VERSION ""

NS_ :

BS_:

BU_: ADAS Master
VAL_TABLE_ TestECUState 1 "ON" 0 "OFF" ;
VAL_TABLE_ vtbSensorReqCause 15 "SNA" 2 "by Request 2" 1 "by Request 1" 0 "normal cycle" ;
VAL_TABLE_ vtbErrorDescription 255 "ERROR" ;

BO_ 3221225472 VECTOR__INDEPENDENT_SIG_MSG: 0 Vector__XXX
 SG_ sig_neg_respond : 0|8@1- (1,0) [0|0] "" Vector__XXX

BO_ 130 AEB_Info_ECU: 1 Vector__XXX
 SG_ sig_aeb_active : 0|1@1+ (1,0) [0|1] "flag"  ADAS

BO_ 515 OBD_Neg_Respond_OBD: 2 Master
 SG_ sig_sid : 8|8@1- (1,0) [0|0] ""  ADAS
 SG_ sig_neg_respond : 0|8@1- (1,0) [0|0] ""  ADAS

BO_ 514 OBD_Pos_Respond_OBD: 1 Master
 SG_ sig_sid : 0|8@1- (1,0) [0|0] ""  ADAS

BO_ 1672 VUM_File_ADAS: 8 Master
 SG_ sig_payload : 0|64@1- (1,0) [0|0] ""  ADAS

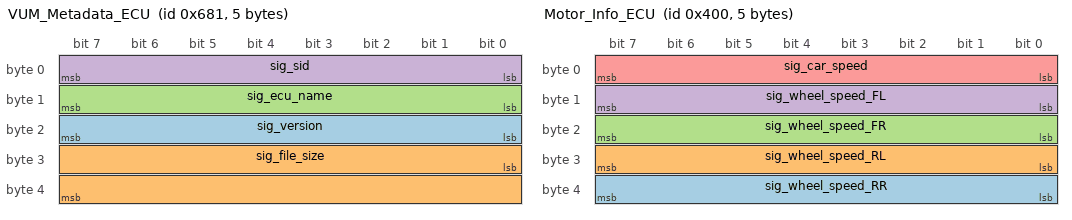
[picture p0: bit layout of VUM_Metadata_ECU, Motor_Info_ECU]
BO_ 1665 VUM_Metadata_ECU: 5 Master
 SG_ sig_version : 16|8@1+ (1,0) [0|255] ""  ADAS
 SG_ sig_file_size : 24|16@1+ (1,0) [0|65535] ""  ADAS
 SG_ sig_ecu_name : 8|8@1+ (1,0) [0|255] ""  ADAS
 SG_ sig_sid : 0|8@1+ (1,0) [0|255] ""  ADAS

BO_ 1664 VUM_Request_ECU: 1 Master
 SG_ sig_sid : 0|8@1- (1,0) [0|0] ""  ADAS

BO_ 1219 Steering_Angle_Info_ECU: 1 Master
 SG_ sig_steering_angle : 0|8@1- (1,0) [0|0] ""  ADAS

BO_ 1057 Transmission_Info_ECU: 1 Master
 SG_ sig_gear_mode : 0|2@1- (1,0) [0|0] ""  ADAS

BO_ 1024 Motor_Info_ECU: 5 Master
 SG_ sig_wheel_speed_RR : 32|8@1- (1,0) [0|0] ""  ADAS
 SG_ sig_wheel_speed_RL : 24|8@1- (1,0) [0|0] ""  ADAS
 SG_ sig_wheel_speed_FR : 16|8@1- (1,0) [0|0] ""  ADAS
 SG_ sig_wheel_speed_FL : 8|8@1- (1,0) [0|0] ""  ADAS
 SG_ sig_car_speed : 0|8@1- (1,0) [0|0] ""  ADAS

BO_ 1286 ADAS_Neg_Respond_OTA: 2 ADAS
 SG_ sig_sid : 8|8@1- (1,0) [0|0] ""  Master
 SG_ sig_neg_respond : 0|8@1- (1,0) [0|0] ""  Master

BO_ 1285 ADAS_Pos_Respond_OTA: 8 ADAS
 SG_ sig_data : 16|56@1- (1,0) [0|0] ""  Master
 SG_ sig_sid : 0|8@1- (1,0) [0|0] ""  Master

BO_ 260 ADAS_Request_OBD: 1 ADAS
 SG_ sig_sid : 0|8@1- (1,0) [0|0] ""  Master

BO_ 259 ADAS_Control_Brake: 1 ADAS
 SG_ sig_control_aeb : 0|1@1- (1,0) [0|0] ""  Master

BO_ 1282 ADAS_Control_Steering: 2 ADAS
 SG_ sig_control_steering : 0|10@1- (1,0) [0|0] ""  Master

BO_ 1281 ADAS_Control_Motor: 2 ADAS
 SG_ sig_control_accerleration : 0|10@1- (1,0) [0|0] ""  Master

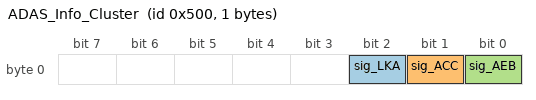
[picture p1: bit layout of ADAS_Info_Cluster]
BO_ 1280 ADAS_Info_Cluster: 1 ADAS
 SG_ sig_LKA : 2|1@1- (1,0) [0|0] ""  Master
 SG_ sig_ACC : 1|1@1- (1,0) [0|0] ""  Master
 SG_ sig_AEB : 0|1@1- (1,0) [0|0] ""  Master

CM_ BO_ 3221225472 "This is a message for not used signals, created by Vector CANdb++ DBC OLE DB Provider.";
BA_DEF_  "DatabaseVersion" STRING ;
BA_DEF_ BO_  "DiagResponse" ENUM  "No","Yes","vector_leerstring";
BA_DEF_ BO_  "DiagRequest" ENUM  "No","Yes","vector_leerstring";
BA_DEF_  "Manufacturer" STRING ;
BA_DEF_ BU_  "NodeLayerModules" STRING ;
BA_DEF_  "BusType" STRING ;
BA_DEF_ SG_  "GenSigSendType" ENUM  "Cyclic","OnWrite","OnWriteWithRepetition","OnChange","OnChangeWithRepetition","IfActive","IfActiveWithRepetition","NoSigSendType","NotUsed","NotUsed","NotUsed","NotUsed","NotUsed";
BA_DEF_ BO_  "GenMsgSendType" ENUM  "Cyclic","NotUsed","NotUsed","NotUsed","NotUsed","Cyclic","NotUsed","IfActive","NoMsgSendType","NotUsed","vector_leerstring";
BA_DEF_ BO_  "GenMsgCycleTime" INT 0 50000;
BA_DEF_ BO_  "GenMsgCycleTimeFast" INT 0 50000;
BA_DEF_ BO_  "GenMsgILSupport" ENUM  "No","Yes";
BA_DEF_DEF_  "DatabaseVersion" "";
BA_DEF_DEF_  "DiagResponse" "No";
BA_DEF_DEF_  "DiagRequest" "No";
BA_DEF_DEF_  "Manufacturer" "Vector";
BA_DEF_DEF_  "NodeLayerModules" "CANoeILNLVector.dll";
BA_DEF_DEF_  "BusType" "CAN";
BA_DEF_DEF_  "GenSigSendType" "Cyclic";
BA_DEF_DEF_  "GenMsgSendType" "NoMsgSendType";
BA_DEF_DEF_  "GenMsgCycleTime" 200;
BA_DEF_DEF_  "GenMsgCycleTimeFast" 20;
BA_DEF_DEF_  "GenMsgILSupport" "Yes";
BA_ "DatabaseVersion" "1.1";
BA_ "DiagResponse" BO_ 515 1;
BA_ "DiagResponse" BO_ 514 1;
BA_ "DiagRequest" BO_ 1664 1;
BA_ "GenMsgCycleTime" BO_ 1219 5;
BA_ "GenMsgCycleTime" BO_ 1057 100;
BA_ "GenMsgCycleTime" BO_ 1024 5;
BA_ "DiagResponse" BO_ 1286 1;
BA_ "DiagResponse" BO_ 1285 1;
BA_ "DiagRequest" BO_ 260 1;
BA_ "GenMsgCycleTime" BO_ 259 5;
BA_ "GenMsgCycleTime" BO_ 1282 10;
BA_ "GenMsgCycleTime" BO_ 1281 10;
BA_ "GenMsgCycleTime" BO_ 1280 100;
